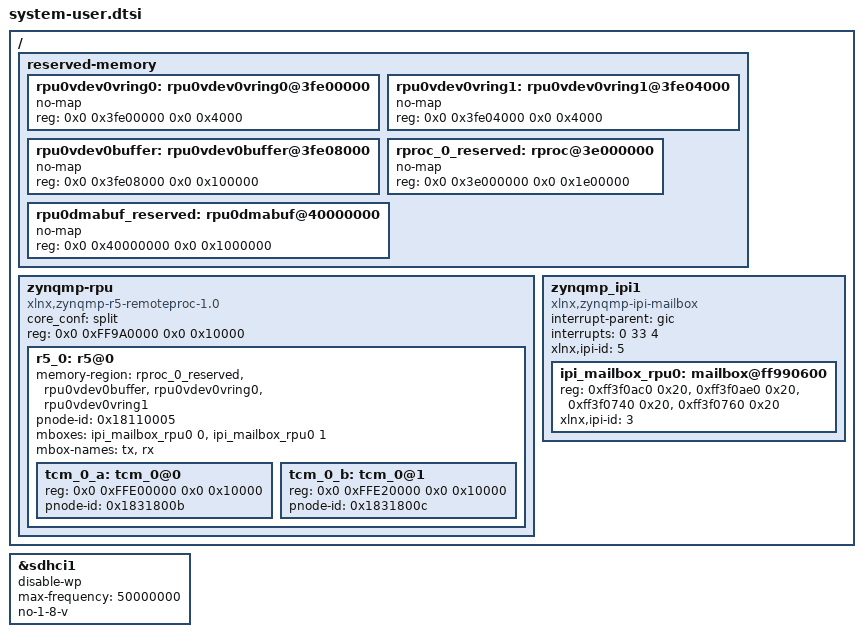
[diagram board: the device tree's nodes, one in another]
/include/ "system-conf.dtsi"
/ {
};
/ {
    reserved-memory {
        #address-cells = <2>;
        #size-cells = <2>;
        ranges;
        rpu0vdev0vring0: rpu0vdev0vring0@3fe00000 {
            no-map;
            reg = <0x0 0x3fe00000 0x0 0x4000>;
        };
        rpu0vdev0vring1: rpu0vdev0vring1@3fe04000 {
            no-map;
            reg = <0x0 0x3fe04000 0x0 0x4000>;
        };
        rpu0vdev0buffer: rpu0vdev0buffer@3fe08000 {
            no-map;
            reg = <0x0 0x3fe08000 0x0 0x100000>;
        };
        rproc_0_reserved: rproc@3e000000 {
            no-map;
            reg = <0x0 0x3e000000 0x0 0x1e00000>;
        };
        rpu0dmabuf_reserved: rpu0dmabuf@40000000 {
            no-map;
            reg = <0x0 0x40000000 0x0 0x1000000>;
        };
    };

    zynqmp-rpu {
        compatible = "xlnx,zynqmp-r5-remoteproc-1.0";
        #address-cells = <2>;
        #size-cells = <2>;
        ranges;
        core_conf = "split";
        reg = <0x0 0xFF9A0000 0x0 0x10000>;
        r5_0: r5@0 {
            #address-cells = <2>;
            #size-cells = <2>;
            ranges;
            memory-region = <&rproc_0_reserved>, <&rpu0vdev0buffer>, <&rpu0vdev0vring0>, <&rpu0vdev0vring1>;
            pnode-id = <0x18110005>;
            mboxes = <&ipi_mailbox_rpu0 0>, <&ipi_mailbox_rpu0 1>;
            mbox-names = "tx", "rx";
            tcm_0_a: tcm_0@0 {
                reg = <0x0 0xFFE00000 0x0 0x10000>;
                pnode-id = <0x1831800b>;
            };
            tcm_0_b: tcm_0@1 {
                reg = <0x0 0xFFE20000 0x0 0x10000>;
                pnode-id = <0x1831800c>;
            };
        };
    };

    zynqmp_ipi1 {
        compatible = "xlnx,zynqmp-ipi-mailbox";
        interrupt-parent = <&gic>;
        interrupts = <0 33 4>;
        xlnx,ipi-id = <5>;
        #address-cells = <1>;
        #size-cells = <1>;
        ranges;

        /* APU<->RPU0 IPI mailbox controller */
        ipi_mailbox_rpu0: mailbox@ff990600 {
            reg = <0xff3f0ac0 0x20>,
                  <0xff3f0ae0 0x20>,
                  <0xff3f0740 0x20>,
                  <0xff3f0760 0x20>;
            reg-names = "local_request_region",
                    "local_response_region",
                    "remote_request_region",
                    "remote_response_region";
            #mbox-cells = <1>;
            xlnx,ipi-id = <3>;
        };
    };
};

&sdhci1{
	status = "okay";
	disable-wp;
	max-frequency = <50000000>;
	no-1-8-v;
};


